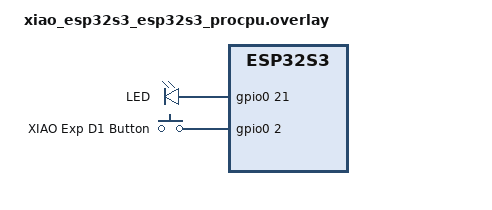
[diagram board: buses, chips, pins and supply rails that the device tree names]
#include <zephyr/dt-bindings/gpio/gpio.h>
#include <zephyr/dt-bindings/input/input-event-codes.h>

/ {
    leds {
        compatible = "gpio-leds";

        led0: led_0 {
            /* XIAO Expansion board LED connected to GPIO1 (or use onboard LED) */
            gpios = <&gpio0 21 GPIO_ACTIVE_HIGH>;
            label = "LED";
        };
    };

    buttons: gpio_keys {
        compatible = "gpio-keys";

        button0: button_0 {
            /* XIAO Expansion board button D1 -> GPIO2 */
            gpios = <&gpio0 2 (GPIO_PULL_UP | GPIO_ACTIVE_HIGH)>;
            label = "XIAO Exp D1 Button";
            zephyr,code = <INPUT_KEY_0>;
        };
    };

    aliases {
        led0 = &led0;
        sw0 = &button0;
    };
};
